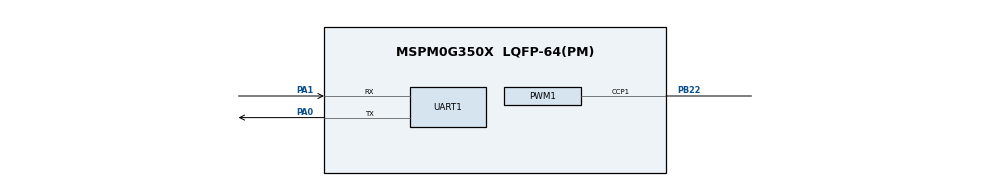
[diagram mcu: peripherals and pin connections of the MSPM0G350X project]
/**
 * @cliArgs --device "MSPM0G350X" --part "Default" --package "LQFP-64(PM)" --product "mspm0_sdk@2.05.01.00"
 * @versions {"tool":"1.24.1+4189"}
 */

/**
 * Import the modules used in this configuration.
 */
const PWM    = scripting.addModule("/ti/driverlib/PWM", {}, false);
const PWM1   = PWM.addInstance();
const SYSCTL = scripting.addModule("/ti/driverlib/SYSCTL");
const TIMER  = scripting.addModule("/ti/driverlib/TIMER", {}, false);
const TIMER1 = TIMER.addInstance();
const UART   = scripting.addModule("/ti/driverlib/UART", {}, false);
const UART1  = UART.addInstance();

/**
 * Write custom configuration values to the imported modules.
 */
const gate7  = system.clockTree["MFCLKGATE"];
gate7.enable = true;

PWM1.$name                              = "PWM_LED";
PWM1.clockDivider                       = 8;
PWM1.ccIndex                            = [1];
PWM1.timerStartTimer                    = true;
PWM1.ccp1PinConfig.direction            = scripting.forceWrite("OUTPUT");
PWM1.ccp1PinConfig.hideOutputInversion  = scripting.forceWrite(false);
PWM1.ccp1PinConfig.onlyInternalResistor = scripting.forceWrite(false);
PWM1.ccp1PinConfig.passedPeripheralType = scripting.forceWrite("Digital");
PWM1.ccp1PinConfig.$name                = "ti_driverlib_gpio_GPIOPinGeneric3";
PWM1.peripheral.$assign                 = "TIMG8";
PWM1.peripheral.ccp1Pin.$assign         = "PB22";
PWM1.PWM_CHANNEL_1.$name                = "ti_driverlib_pwm_PWMTimerCC0";

const Board = scripting.addModule("/ti/driverlib/Board", {}, false);

SYSCTL.forceDefaultClkConfig = true;
SYSCTL.clockTreeEn           = true;

TIMER1.$name              = "TIMER_0";
TIMER1.timerClkDiv        = 8;
TIMER1.timerClkPrescale   = 100;
TIMER1.timerMode          = "PERIODIC";
TIMER1.timerStartTimer    = true;
TIMER1.timerPeriod        = "1000 ms";
TIMER1.interrupts         = ["ZERO"];
TIMER1.peripheral.$assign = "TIMG0";

UART1.uartClkSrc                       = "MFCLK";
UART1.enabledInterrupts                = ["RX"];
UART1.$name                            = "UART_Emm";
UART1.targetBaudRate                   = 115200;
UART1.peripheral.$assign               = "UART0";
UART1.peripheral.rxPin.$assign         = "PA1";
UART1.peripheral.txPin.$assign         = "PA0";
UART1.txPinConfig.direction            = scripting.forceWrite("OUTPUT");
UART1.txPinConfig.hideOutputInversion  = scripting.forceWrite(false);
UART1.txPinConfig.onlyInternalResistor = scripting.forceWrite(false);
UART1.txPinConfig.passedPeripheralType = scripting.forceWrite("Digital");
UART1.txPinConfig.$name                = "ti_driverlib_gpio_GPIOPinGeneric0";
UART1.rxPinConfig.hideOutputInversion  = scripting.forceWrite(false);
UART1.rxPinConfig.onlyInternalResistor = scripting.forceWrite(false);
UART1.rxPinConfig.passedPeripheralType = scripting.forceWrite("Digital");
UART1.rxPinConfig.$name                = "ti_driverlib_gpio_GPIOPinGeneric1";

/**
 * Pinmux solution for unlocked pins/peripherals. This ensures that minor changes to the automatic solver in a future
 * version of the tool will not impact the pinmux you originally saw.  These lines can be completely deleted in order to
 * re-solve from scratch.
 */
Board.peripheral.$suggestSolution          = "DEBUGSS";
Board.peripheral.swclkPin.$suggestSolution = "PA20";
Board.peripheral.swdioPin.$suggestSolution = "PA19";
